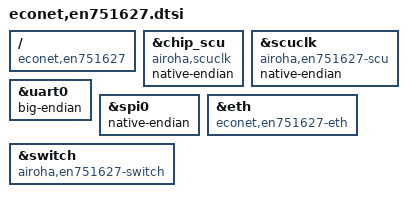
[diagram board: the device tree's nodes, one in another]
// SPDX-License-Identifier: (GPL-2.0-only OR BSD-2-Clause)
/* EN7516/EN7527 is the big-endian member of the EN7528 family. */
#include "econet,en7528.dtsi"

/ {
	compatible = "econet,en751627", "airoha,en751627";
};

&chip_scu {
	compatible = "airoha,scuclk", "airoha,en751627-chip-scu",
		     "airoha,en7528-chip-scu", "syscon";
	native-endian;
};

&scuclk {
	compatible = "airoha,en751627-scu", "airoha,en7528-scu", "syscon";
	native-endian;
};

&uart0 {
	big-endian;
};

&spi0 {
	native-endian;
};

&eth {
	compatible = "econet,en751627-eth";
};

&switch {
	compatible = "airoha,en751627-switch", "airoha,en7528-switch";
};
